# MMCSD8_MMC_CTLCFG_0FA00000h register map
Vendor: Texas Instruments
Peripheral module from a debugger description file (folder AM275x).
Registers are 16-bit, read-write, reset 0x0 unless marked. A register's access mark holds for its fields unless they carry their own. Offsets are as the file gives them; lines under a group give offsets from that group; [hi:lo] are bit positions; {n}, {i} and the like mark numbered series; 'fields as' and 'values as' point back to an identical list; <NAME> marks a mode.

## mmc_ctlcfg (part 1 of 4)
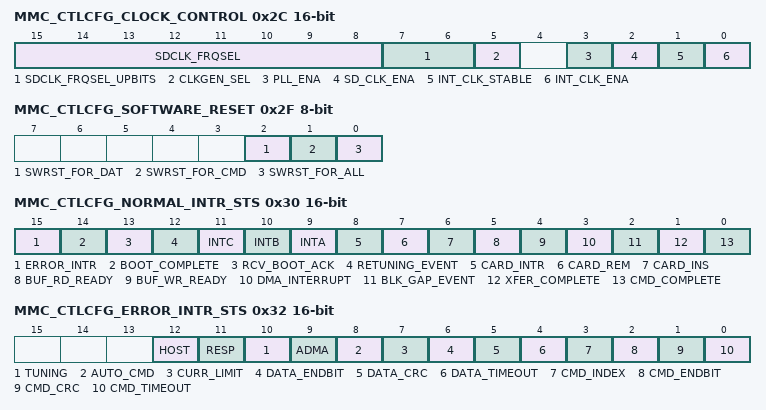
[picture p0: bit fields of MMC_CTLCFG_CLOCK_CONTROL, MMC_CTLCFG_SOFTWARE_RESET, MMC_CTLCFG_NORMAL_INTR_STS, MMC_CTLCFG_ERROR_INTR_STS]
0x2C MMC_CTLCFG_CLOCK_CONTROL access per field — This register is used to program the Clock frequency select, generator select, Clock enable, Internal Clock state fields This register controls SDCLK in SD Mode and RCLK in UHS-II mode.
  [15:8] SDCLK_FRQSEL rw — This register is used to select the frequency of the SDCLK pin. The frequency is not programmed directly; rather this register holds the divisor of the Base Clock Frequency For SD clock in the capabilities register. Only the following settings are allowed. [1] 8-bit Divided Clock Mode 80h - base clock divided by 256 40h - base clock divided by 128 20h - base clock divided by 64 10h - base clock divided by 32 08h - base clock divided by 16 04h - base clock divided by 8 02h - base clock divided by 4 01h - base clock divided by 2 00h - base clock[10MHz-63MHz]Setting 00h specifies the highest frequency of the SD Clock. When setting multiple bits, the most significant bit is used as the divisor. But multiple bits should not be set. The two default divider values can be calculated by the frequency that is defined by the Base Clock Frequency For SD Clock in the Capabilities register. [1] 25 MHz divider value. [2] 400 KHz divider value.The frequency of the SDCLK is set by the following formula:Clock Frequency = [Baseclock] / divisor.Thus choose the smallest possible divisor which results in a clock frequency that is less than or equal to the target frequency.Maximum Frequency for SD = 50Mhz [base clock]Maximum Frequency for MMC = 52Mhz [base clock]Minimum Frequency = 195.3125Khz [50Mhz / 256], same calculation for MMC also. [2] 10-bit Divided Clock ModeHost Controller Version 3.00 supports this mandatory mode instead of the 8-bit Divided Clock Mode. The length of divider is extended to10 bits and all divider values shall be supported. 3FFh --1/2046 Divided Clock N -------1/2N Divided Clock [Duty 50%] 002h -- 1/4 Divided Clock 001h ---1/2 Divided Clock 000h --- Base Clock [10MHz-254MHz] Reset Source: vbus_amod_g_rst_n
  [7:6] SDCLK_FRQSEL_UPBITS rw — Bit 07-06 is assigned to bit 09-08 of clock divider in SDCLK Frequency Select. Reset Source: vbus_amod_g_rst_n
  [5] CLKGEN_SEL rw — This bit is used to select the clock generator mode in SDCLK Frequency Select. If the Programmable Clock Mode is supported [non-zero value is set to Clock Multiplier in the Capabilities register], this bit attribute is RW, and if not supported, this bit attribute is RO and zero is read. This bit depends on the setting of Preset Value Enable in the Host Control 2 register. If the Preset Value Enable = 0, this bit is set by Host Driver. If the Preset Value Enable = 1, this bit is automatically set to a value specified in one of Preset Value registers. '0' Divided Clock Mode '1' Programmable Clock Mode 0 Divided Clock Mode1 Programmable Clock Mode
  [3] PLL_ENA rw — This bit is added from Version 4.10 for Host Controller using PLL. This feature allows Host Controller to initialize clock generator in two steps: by Internal Clock Enable and PLL Enable and to minimize output latency [ex. SDCLK/RCLK, D0lane] from SD Clock Enable. There are two modes to keep Host Drivers compatibility. In both modes, PLL Locked timing is indicated by Internal Clock Stable. [1] When Host Version 4 Enable =0 [Host Driver Version 3, which does not support this bit] or this bit is not implemented,Internal Clock Enable [or SD Clock Enable] may activate PLL [exit low power mode and start locking clock]. [2] When Host Version 4 Enable =1 [Host Driver Version 4],Internal Clock Enable is set before setting this bit and then setting this bit may activate PLL [exit low power mode and start locking clock]. 0 PLL is in low power mode1 PLL is enabled
  [2] SD_CLK_ENA rw — The HC shall stop SDCLK when Writing this bit to 0. SDCLK frequency Select can be changed when this bit is 0. Then, the HC shall maintain the same clock frequency until SDCLK is stopped [Stop at SDCLK = 0]. If the HC detects the No Card state, this bit shall be cleared. 0 Disable providing SDCLK1 Enable providing SDCLK
  [1] INT_CLK_STABLE ro — This bit is set to 1 when SD clock is stable after Writing to Internal Clock Enable in this register to 1. The SD Host Driver shall wait to set SD Clock Enable until this bit is set to 1. Note: This is useful when using PLL for a clock oscillator that requires setup time. 0 Not Ready1 Ready
  [0] INT_CLK_ENA rw — This bit is set to 0 when the HD is not using the HC or the HC awaits a wakeup event. The HC should stop its internal clock to go very low power state. Still, registers shall be able to be read and written. Clock starts to oscillate when this bit is set to 1. When clock oscillation is stable, the HC shall set Internal Clock Stable in this register to 1. This bit shall not affect card detection. 0 Stop1 Oscillate
0x2E MMC_CTLCFG_TIMEOUT_CONTROL 8-bit — The register sets the Data Timeout counter value
  [3:0] COUNTER_VALUE — This value determines the interval by which DAT line time-outs are detected. Refer to the Data Time-out Error in the Error Interrupt Status register for information on factors that dictate time-out generation. Time-out clock frequency will be generated by dividing the sdclockTMCLK by this value. When setting this register, prevent inadvertent time-out events by clearing the Data Time-out Error Status Enable [in the Error Interrupt Status Enable register]. 1111 - Reserved 1110 - TMCLK * 2^27 -------------------- -------------------- 0001 - TMCLK * 2^14 0000 - TMCLK * 2^13 Reset Source: vbus_amod_g_rst_n
0x2F MMC_CTLCFG_SOFTWARE_RESET 8-bit — This register is used to program the software reset for data, command and for all
  [2] SWRST_FOR_DAT — Only part of data circuit is reset. The following registers and bits are cleared by this bit: Buffer Data Port Register: Buffer is cleared and Initialized. Present State register: Buffer read Enable, Buffer write Enable, Read Transfer Active, Write Transfer Active, DAT Line Active, Command Inhibit [DAT]. Block Gap Control register: Continue Request, Stop At Block Gap Request. Normal Interrupt Status register: Buffer Read Ready, Buffer Write Ready, Block Gap Event, Transfer Complete. 0 Work1 Reset
  [1] SWRST_FOR_CMD — Software Reset For CMD Line Only part of command circuit is reset to be able to issue a command. From Version 4.10, this bit is also used to initialize UHS-II command circuit. This reset is effective only command issuing circuit [including response error statuses related to Com-mand Inhibit [CMD] control] and does not affect data transfer circuit. Host Controller can continue data transfer even this reset is executed during handling of sub com- mand response errors. The following registers and bits are cleared by this bit: Present State register Command Inhibit [CMD] Normal Interrupt Status register Command Complete Error Interrupt Status [from Version 4.10] Response error statuses related to Com-mand Inhibit [CMD] 0 Work1 Reset
  [0] SWRST_FOR_ALL — This reset affects the entire HC except for the card detection circuit. Register bits of type ROC, RW, RW1C, RWAC are cleared to 0. During its initialization, the HD shall set this bit to 1 to reset the HC. The HC shall reset this bit to 0 when capabilities registers are valid and the HD can read them. Additional use of Software Reset For All may not affect the value of the Capabilities registers. If this bit is set to 1, the SD card shall reset itself and must be re initialized by the HD. 0 Work1 Reset
0x30 MMC_CTLCFG_NORMAL_INTR_STS access not given — This register gives the status of all the interrupts
  [15] ERROR_INTR ro — If any of the bits in the Error Interrupt Status Register are set, then this bit is set. Therefore the HD can test for an error by checking this bit first. In UHS-II mode is enabled, if any of the bits in the UHS-II Error Interrupt Status register are set, this bit is also set. '0' No error '1' Error 0 No Interrupt1 Error interrupt is generated
  [14] BOOT_COMPLETE — This status is set if the boot operation gets terminated. '0' Boot operation is not terminated '1' Boot operation is terminated 0 No Interrupt1 Boot Terminate interrupt is generated (access R/W1TC)
  [13] RCV_BOOT_ACK — This status is set if the boot acknowledge is received from device. '0' Boot ack not recieved '1' Boot ack is recieved 0 No Interrupt1 Boot acknowledge is received (access R/W1TC)
  [12] RETUNING_EVENT ro — This status is set if Re-Tuning Request in the Present State register changes from 0 to 1. Host Controller requests Host Driver to perform re-tuning for next data transfer. Current data transfer [not large block count] can be completed without re-tuning.In UHS-II mode, this bit is not effective '0' Re-tuning not required '1' Re-tuning should be performed Reset Source: vbus_amod_g_rst_n
  [11] INTC ro — This status is set if INT_C is enabled and INT_C# pin is in low level. Writing this bit to 1 does not clear this bit. It is cleared by resetting the INT_C interrupt factor. Reset Source: vbus_amod_g_rst_n
  [10] INTB ro — This status is set if INT_B is enabled and INT_B# pin is in low level. Writing this bit to 1 does not clear this bit. It is cleared by resetting the INT_B interrupt factor. Reset Source: vbus_amod_g_rst_n
  [9] INTA ro — This status is set if INT_A is enabled and INT_A# pin is in low level. Writing this bit to 1 does not clear this bit. It is cleared by resetting the INT_A interrupt factor.NOTE : INT_A, INT_B, and INT_C are to be implemented based on the Application Requirements. By default these are not implemented as there is no specific requirement from Customers. Reset Source: vbus_amod_g_rst_n
  [8] CARD_INTR ro — When this status has been set and the Host Driver needs to start this interrupt service, Card Interrupt Status Enable in the Normal Interrupt Status Enable register may be set to 0 in order to clear the card interrupt status latched in the Host Controller and to stop driv-ing the interrupt signal to the Host System.After completion of the card interrupt service [It should reset interrupt factors in the SD card and the interrupt signal may not be asserted],set Card Interrupt Status Enable to 1 and start sampling the interrupt signal again. Writing this bit to 1 does not clear this bit. It is cleared by resetting the SD card interrupt fac-tor. [1] DAT[1] Interrupt Input in SD Mode In 1-bit mode, the Host Controller shall detect the Card Interrupt without SD Clock to support wakeup. In 4-bit mode, the card interrupt sig-nal is sampled during the interrupt cycle, so there are some sample delays between the interrupt signal from the SD card and the inter-rupt to the Host System. Interrupt detected by DAT[1] is supported when there is a card per slot. In case of UHS-I mode, switching time of Interrupt Period is relaxed for 2 clock cycles. Then Host Controller needs to delay start of interrupt sampling at least 2 clocks and should sample interrupt while Interrupt Period is sta-ble. [2] DAT[2] Interrupt Input in UHS-II Mode When Card Inserted in the Present State reg-ister and SD Bus Power for VDD1 in the Power Control register are set to 1, Host Con-troller configures DAT[2] as Interrupt Input and enables pull-up of DAT[2]. DAT[2] interrupt is asynchronous to RCLK, low level sensitive and 3.3V signal level. DAT[2] interrupt is masked by setting Card Interrupt Status Enable to 0 in the Normal Interrupt register.When either Card Inserted or SD Bus Power for VDD1 is set to 0, Host Controller sets DAT[2] to low. Only point to point connection is allowed between Host and Card. [3] INT MSG in UHS-II Mode INT MSG is enabled by setting INT MSG Enable in the UHS-II Device Select register. DAT[2] and INT MSG interrupt sources are ORed and indicated to Card Interrupt. If any bit in the UHS-II Device Interrupt Status regis- ter is set to 1, INT MSG interrupt is generated. INT MSG interrupt is cleared by Writing a cor-respondent bit to 1 in the UHS-II Device Inter-rupt Status register. Masking DAT[2] interrupt also disables INT MSG interupt due to Card Interrupt Status Enable is set to 0. SDIO Ver-sion 4.00 does not support INT MSG. '0' No Card Interrupt '1' Generate Card Interrupt 0 No Interrupt1 Card interrupt is generated
  [7] CARD_REM — This status is set if the Card Inserted in the Present State register changes from 1 to 0. When the HD writes this bit to 1 to clear this status the status of the Card Inserted in the Present State register should be confirmed. Because the card detect may possibly be changed when the HD clear this bit an Interrupt event may not be generated. '0' Card State Stable or Debouncing '1' Card Removed 0 No Interrupt1 Card removal interrupt is generated (access R/W1TC)
  [6] CARD_INS — This status is set if the Card Inserted in the Present State register changes from 0 to 1.When the HD writes this bit to 1 to clear this status the status of the Card Inserted in the Present State register should be confirmed. Because the card detect may possibly be changed when the HD clear this bit an Interrupt event may not be generated. '0' Card State Stable or Debouncing '1' Card Inserted 0 No Interrupt1 Card insertion interrupt is generated (access R/W1TC)
  [5] BUF_RD_READY — This status is set if the Buffer Read Enable changes from 0 to 1. Buffer Read Ready is set to 1 for every CMD19 execution in tuning procedure.In UHS-II mode, this bit is set at FC [Flow Control] unit basis. '0' Not ready to read buffer, '1' Ready to read buffer 0 No Interrupt1 Buffer Read Ready interrupt is generated (access R/W1TC)
  [4] BUF_WR_READY — This status is set if the Buffer Write Enable changes from 0 to 1.In UHS-II mode, this bit is set at FC [Flow Control] unit basis. '0' Not ready to write to buffer, '1' Ready to write to buffer 0 No Interrupt1 Buffer Write Ready interrupt is generated (access R/W1TC)
  [3] DMA_INTERRUPT — This status is set if the HC detects the Host DMA Buffer Boundary in the Block Size regiser. '0' No DMA Interrupt '1' DMA Interrupt is generated 0 No Interrupt1 DMA interrupt is generated (access R/W1TC)
  [2] BLK_GAP_EVENT — If the Stop At Block Gap Request in the BlockGap Control Register is set, this bit is set. Read Transaction:This bit is set at the falling edge of the DAT Line Active Status [When the transaction is stopped at SD Bus timing. The Read Wait must be supported inorder to use this function]. Write Transaction:This bit is set at the falling edge of Write Transfer Active Status [After getting CRC status at SD Bus timing]. In UHS-II mode, this bit is set at FC [Flow Control] unit basis. '0' No Block Gap Event '1' Transaction stopped at Block Gap 0 No Interrupt1 Block Gap Event is generated (access R/W1TC)
  [1] XFER_COMPLETE — This bit is set when a read / write transaction is completed. SD Mode Read Transaction:This bit is set at the falling edge of Read Transfer Active Status. There are two cases in which the Interrupt is generated. The first is when a data transfer is completed as specified by data length [After the last data has been read to the Host Sys- tem]. The second is when data has stopped at the block gap and completed the data transfer by setting the Stop At Block Gap Request in the Block Gap Control Register [After valid data has been read to the Host System]. Write Transaction:This bit is set at the falling edge of the DAT Line Active Status. There are two cases in which the Interrupt is generated. The first is when the last data is written to the card as specified by data length and Busy signal is released. The second is when data transfers are stopped at the block gap by setting Stop At Block Gap Request in the Block Gap Control Register and data transfers completed. [After valid data is written to the SD card and the busy signal is released].Note: Transfer Complete has higher priority than Data Time-out Error. If both bits are set to 1, the data transfer can be considered complete.Note: While performing tuning procedure [Execute Tuning is set to 1], Transfer Complete is not set to 1 Command with Busy:This bit is set when busy is de-asserted. Refer to DAT Line Active and Command Inhibit[DAT] in the Present State register.UHS-I mode While performing tuning procedure [Execute Tuning is set to 1], Transfer Complete is not set to 1. '0' No Data Transfer Complete, '1' Data Transfer Complete UHS-II Mode This interrupt is generated in following twocases: [a] EBSY Completion [for EBSY supported commands] When EBSY Wait in the UHS-II Transfer Mode register is set to 1, this bit is set when EBSY packet has been received, and all valid data have been sent to system memory in case of read operation. [b] Stop and Continue during DCMD Data Transfer When Stop At Block Gap Request in the Block Gap Control register is set to 1 and data transfer is stopped at the Flow Control. Following is for both SD mode and UHS-II mode.The table below shows that Transfer Com-plete has higher priority than Data Timeout Error. If both bits are set to 1, execution of a command can be considered to be completed. 1 - Command execution is completed 0 - Not complete 0 No Interrupt1 Transfer complete interrupt is generated (access R/W1TC)
  [0] CMD_COMPLETE — SD Mode This bit is set when we get the end bit of the command response [Except Auto CMD12 and Auto CMD23]Note: Command Time-out Error has higher priority than Command Complete. If both are set to 1, it can be considered that the response was not received correctly.Version 4.00 defines response check function for R1 and R5. If Response Interrupt Disable in the Transfer Mode register is set to 1, gen-eration of this interrupt is prohibited regardless of Command Complete Signal Enable. UHS-II ModeIf Response Interrupt Disable is set to 0 in the UHS-II Transfer Mode register, this interrupt is generated when response packet is received.If Response Interrupt Disable is set to 1 in the UHS-II Transfer Mode register, generation of this interrupt is prohibited regardless of Com-mand Complete Signal Enable. '0' No Command Complete, '1' Command Complete 0 No Interrupt1 Command complete interrupt is generated (access R/W1TC)
0x32 MMC_CTLCFG_ERROR_INTR_STS access not given — This register gives the status of the error interrupts
  [12] HOST — Occurs when detecting ERROR in m_hresp[dma transaction] 0 No Error1 Host Error (access R/W1TC)
  [11] RESP — Host Controller Version 4.00 supports response error check function to avoid overhead of response error check by Host Driver during DMA execution. If Response Error Check Enable is set to 1 in the Transfer Mode register, Host Controller Checks R1 or R5 response. If an error is detected in a response, this bit is set to 1.If Response Error Check Enable is set to 1 in the Transfer Mode register, Host Controller Checks R1 or R5 response. 0 No Error1 Response Error (access R/W1TC)
  [10] TUNING — This bit is set when an unrecoverable error is detected in a tuning circuit except during tuning procedure [Occurrence of an error during tuning procedure is indicated by Sampling Select]. By detectingTuning Error, Host Driver needs to abort a command executing and perform tuning.To reset tuning circuit, Sampling Clock shall be set to 0 before executing tuning procedure.The Tuning Error is higher priority than the other error interrupts generated during data transfer. By detecting Turning Error, the Host Driver should discard data transferred by a current read/write command and retry data transfer after the Host Controller retrieved from tuning circuit error. 0 No Error1 Tuning Error (access R/W1TC)
  [9] ADMA — This bit is set when the Host Controller detects errors during ADMA based data transfer. The state of the ADMA at an error occurrence is saved in the ADMA Error Status Register. 0 No Error1 ADMA Error (access R/W1TC)
  [8] AUTO_CMD — Auto CMD12 and Auto CMD23 use this error status.This bit is set when detecting that any of the bits D00 to D05 in Auto CMD Error Status register has changed from 0 to 1. D07 is effective in case of Auto CMD12. Auto CMD Error Status register is valid while this bit is set to 1 and may be cleared with clearing of this bit [another implementation is also allowed]. 0 No Error1 Auto CMD Error (access R/W1TC)
  [7] CURR_LIMIT — By setting the SD Bus Power bit in the Power Control Register, the HC is requested to supply power for the SD Bus. If the HC supports the Current Limit Function, it can be protected from an Illegal card by stopping power supply to the card in which case this bit indicates a failure status. Reading 1 means the HC is not supplying power to SD card due to some failure. Reading 0 means that the HC is supplying power and no error has occurred. This bit shall always set to be 0, if the HC does not support this function. 0 No Error1 Power Fail (access R/W1TC)
  [6] DATA_ENDBIT — Occurs when detecting 0 at the end bit position of read data which uses the DAT line or the end bit position of the CRC status. 0 No Error1 Data Endbit Error (access R/W1TC)
  [5] DATA_CRC — Occurs when detecting CRC error when transferring read data which uses the DAT line or when detecting the Write CRC Status having a value of other than 010. 0 No Error1 Data CRC Error (access R/W1TC)
  [4] DATA_TIMEOUT — Occurs when detecting one of following timeout conditions: 1. Busy Timeout for R1b, R5b type. 2. Busy Timeout after Write CRC status 3. Write CRC status Timeout 4. Read Data Timeout. 0 No Error1 Data Timeout Error (access R/W1TC)
  [3] CMD_INDEX — Occurs if a Command Index error occurs in the Command Response. 0 No Error1 Command Index Error (access R/W1TC)
  [2] CMD_ENDBIT — Occurs when detecting that the end bit of a command response is 0. 0 No Error1 Command End bit Error (access R/W1TC)
  [1] CMD_CRC — Command CRC Error is generated in two cases. 1. If a response is returned and the Command Time-out Error is set to 0, this bit is set to 1 when detecting a CRT error in the command response 2. The HC detects a CMD line conflict by monitoring the CMD line when a command is issued. If the HC drives the CMD line to 1 level, but detects 0 level on the CMD line at the next SDCLK edge, then the HC shall abort the command [Stop driving CMD line] and set this bit to 1. The Command Timeout Error shall also be set to 1 to distinguish CMD line conflict. 0 No Error1 Command CRC Error (access R/W1TC)
  [0] CMD_TIMEOUT — Occurs only if the no response is returned within 64 SDCLK cycles from the end bit of the command. If the HC detects a CMD line conflict, in which case Command CRC Error shall also be set. This bit shall be set without waiting for 64 SDCLK cycles because the command will be aborted by the HC. 0 No Error1 Command Timeout Error (access R/W1TC)
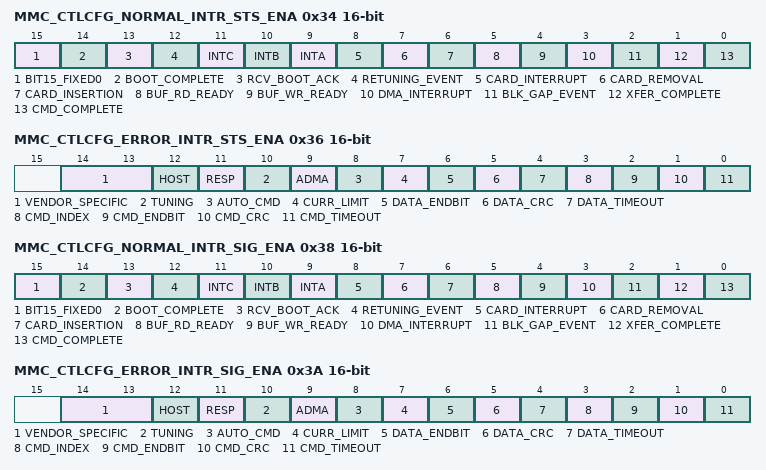
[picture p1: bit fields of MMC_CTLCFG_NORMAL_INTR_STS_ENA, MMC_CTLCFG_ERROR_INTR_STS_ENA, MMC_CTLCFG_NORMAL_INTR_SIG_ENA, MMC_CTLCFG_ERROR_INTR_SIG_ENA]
0x34 MMC_CTLCFG_NORMAL_INTR_STS_ENA access per field — This register is used to enable the normal interrupt status register fields
  [15] BIT15_FIXED0 ro — The HC shall control error Interrupts using the Error Interrupt Status Enable register. Reset Source: vbus_amod_g_rst_n
  [14] BOOT_COMPLETE rw — '0' Masked '1' Enabled 0 Masked1 Enabled
  [13] RCV_BOOT_ACK rw — '0' Masked '1' Enabled 0 Masked1 Enabled
  [12] RETUNING_EVENT rw — 0 - Masked 1 - Enabled 0 Masked1 Enabled
  [11] INTC rw — If this bit is set to 0, the Host Controller shall clear the interrupt request to the System. The Host Driver may clear this bit before servicing the INT_C and may set this bit again after all interrupt requests to INT_C pin are cleared to prevent inadvertent interrupts. 0 Masked1 Enabled
  [10] INTB rw — If this bit is set to 0, the Host Controller shall clear the interrupt request to the System. The Host Driver may clear this bit before servicing the INT_B and may set this bit again after all interrupt requests to INT_B pin are cleared to prevent inadvertent interrupts. 0 Masked1 Enabled
  [9] INTA rw — If this bit is set to 0, the Host Controller shall clear the interrupt request to the System. The Host Driver may clear this bit before servicing the INT_A and may set this bit again after all interrupt requests to INT_A pin are cleared to prevent inadvertent interrupts. 0 Masked1 Enabled
  [8] CARD_INTERRUPT rw — If this bit is set to 0, the HC shall clear Interrupt request to the System. The Card Interrupt detection is stopped when this bit is cleared and restarted when this bit is set to 1. The HD may clear the Card Interrupt Status Enable before servicing the Card Interrupt and may set this bit again after all Interrupt requests from the card are cleared to prevent inadvertent Interrupts. By setting this bit to 0, interrupt input should be masked by implementation so that the interrupt Input is not affected by external signal in any state [ex. floating]. 0 Masked1 Enabled
  [7] CARD_REMOVAL rw — '0' Masked '1' Enabled 0 Masked1 Enabled
  [6] CARD_INSERTION rw — '0' Masked '1' Enabled 0 Masked1 Enabled
  [5] BUF_RD_READY rw — '0' Masked '1' Enabled 0 Masked1 Enabled
  [4] BUF_WR_READY rw — '0' Masked '1' Enabled 0 Masked1 Enabled
  [3] DMA_INTERRUPT rw — '0' Masked, '1' Enabled 0 Masked1 Enabled
  [2] BLK_GAP_EVENT rw — '0' Masked '1' Enabled 0 Masked1 Enabled
  [1] XFER_COMPLETE rw — '0' Masked '1' Enabled 0 Masked1 Enabled
  [0] CMD_COMPLETE rw — '0' Masked '1' Enabled 0 Masked1 Enabled
0x36 MMC_CTLCFG_ERROR_INTR_STS_ENA — This register is used to enable the Error Interrupt Status register fields
  [14:13] VENDOR_SPECIFIC — N/A Reset Source: vbus_amod_g_rst_n
  [12] HOST — '0' Masked '1' Enabled 0 Masked1 Enabled
  [11] RESP — '0' Masked '1' Enabled 0 Masked1 Enabled
  [10] TUNING — '0' Masked '1' Enabled 0 Masked1 Enabled
  [9] ADMA — '0' Masked '1' Enabled 0 Masked1 Enabled
  [8] AUTO_CMD — '0' Masked '1' Enabled 0 Masked1 Enabled
  [7] CURR_LIMIT — '0' Masked '1' Enabled 0 Masked1 Enabled
  [6] DATA_ENDBIT — '0' Masked '1' Enabled 0 Masked1 Enabled
  [5] DATA_CRC — '0' Masked '1' Enabled 0 Masked1 Enabled
  [4] DATA_TIMEOUT — '0' Masked '1' Enabled 0 Masked1 Enabled
  [3] CMD_INDEX — '0' Masked '1' Enabled 0 Masked1 Enabled
  [2] CMD_ENDBIT — '0' Masked '1' Enabled 0 Masked1 Enabled
  [1] CMD_CRC — '0' Masked '1' Enabled 0 Masked1 Enabled
  [0] CMD_TIMEOUT — '0' Masked '1' Enabled 0 Masked1 Enabled
0x38 MMC_CTLCFG_NORMAL_INTR_SIG_ENA access per field — This register is used to enable the Normal Interrupt Signal register
  [15] BIT15_FIXED0 ro — The HD shall control error Interrupts using the Error Interrupt Signal Enable register. Reset Source: vbus_amod_g_rst_n
  [14] BOOT_COMPLETE rw — '0' Masked '1' Enabled 0 Masked1 Enabled
  [13] RCV_BOOT_ACK rw — '0' Masked '1' Enabled 0 Masked1 Enabled
  [12] RETUNING_EVENT rw — '0' Masked '1' Enabled 0 Masked1 Enabled
  [11] INTC rw — '0' Masked '1' Enabled 0 Masked1 Enabled
  [10] INTB rw — '0' Masked '1' Enabled 0 Masked1 Enabled
  [9] INTA rw — '0' Masked '1' Enabled 0 Masked1 Enabled
  [8] CARD_INTERRUPT rw — '0' Masked '1' Enabled 0 Masked1 Enabled
  [7] CARD_REMOVAL rw — '0' Masked '1' Enabled 0 Masked1 Enabled
  [6] CARD_INSERTION rw — '0' Masked '1' Enabled 0 Masked1 Enabled
  [5] BUF_RD_READY rw — '0' Masked '1' Enabled 0 Masked1 Enabled
  [4] BUF_WR_READY rw — '0' Masked '1' Enabled 0 Masked1 Enabled
  [3] DMA_INTERRUPT rw — '0' Masked '1' Enabled 0 Masked1 Enabled
  [2] BLK_GAP_EVENT rw — '0' Masked '1' Enabled 0 Masked1 Enabled
  [1] XFER_COMPLETE rw — '0' Masked '1' Enabled 0 Masked1 Enabled
  [0] CMD_COMPLETE rw — '0' Masked '1' Enabled 0 Masked1 Enabled
0x3A MMC_CTLCFG_ERROR_INTR_SIG_ENA — This register is used to enable Error Interrupt Signal register
  fields as MMC_CTLCFG_ERROR_INTR_STS_ENA
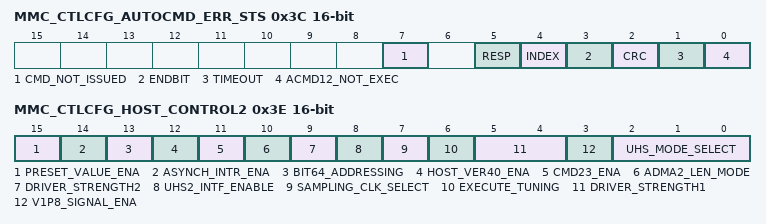
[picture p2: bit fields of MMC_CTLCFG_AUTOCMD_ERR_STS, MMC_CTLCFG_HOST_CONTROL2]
0x3C MMC_CTLCFG_AUTOCMD_ERR_STS ro — This register is used to indicate CMD12 response error of Auto CMD12 and CMD23 response error of Auto CMD 23
  [7] CMD_NOT_ISSUED — Setting this bit to 1 means CMD_wo_DAT is not executed due to an Auto CMD12 error [D04- D01] in this register. This bit is set to 0 when Auto CMD Error is generated by Auto CMD23. 0 No Error1 Not Issued
  [5] RESP — This bit is set when Response Error Check Enable in the Transfer Mode register is set to 1 and an error is detected in R1 response of either Auto CMD12 or Auto CMD23. This status should be ignored if any bit of D00 to D04 is set to 1. 0 No Error1 Auto Command Response Error
  [4] INDEX — Occurs if the Command Index error occurs in response to a command. 0 No Error1 Auto Command Index Error
  [3] ENDBIT — Occurs when detecting that the end bit of command response is 0. 0 No Error1 Auto Command End Bit Error
  [2] CRC — Occurs when detecting a CRC error in the command response. 0 No Error1 Auto Command CRC Error
  [1] TIMEOUT — Occurs if the no response is returned within 64 SDCLK cycles from the end bit of the command.If this bit is set to 1, the other error status bits [D04 - D02] are meaningless. 0 No Error1 Auto Command Timeout Error
  [0] ACMD12_NOT_EXEC — If memory multiple block data transfer is not started due to command error, this bit is not set because it is not necessary to issue Auto CMD12. Setting this bit to 1 means the HC cannot issue Auto CMD12 to stop memory multiple block transfer due to some error. If this bit is set to 1, other error status bits [D04 - D01] are meaningless. This bit is set to 0 when Auto CMD Error is generated by Auto CMD23 0 No Error1 Not Executed
0x3E MMC_CTLCFG_HOST_CONTROL2 — This register is used to program UHS Select Mode,UHS Select Mode,Driver Strength Select,Execute Tuning,Sampling Clock Select,Asynchronous Interrupt Enable and Preset value enable
  [15] PRESET_VALUE_ENA — Host Controller Version 3.00 supports this bit. As the operating SDCLK frequency and I/O driver strength depend on the Host System implementation, it is difficult to determine these parameters in the Standard Host Driver. When Preset Value Enable is set to automatic. This bit enables the functions defined in the Preset Value registers.If this bit is set to 0, SDCLK Frequency Select, Clock Generator Select in the Clock Control register and Driver Strength Select in Host Control 2 register are set by Host Driver.If this bit is set to 1, SDCLK Frequency Select, Clock Generator Select in the Clock Control register and Driver Strength Select in Host Control 2 register are set by Host Controller as specified in the Preset Value registers. 0 SDCLK and Driver Strength are controlled by Host Driver1 Automatic Selection by Preset Value are Enabled
  [14] ASYNCH_INTR_ENA — This bit can be set to 1 if a card support asynchronous interrupt and Asynchronous Interrupt Support is set to 1 in the Capabilities register. Asynchronous interrupt is effective when DAT[1] interrupt is used in 4-bit SD mode [and zero is set to Interrupt Pin Select in the Shared Bus Control register]. If this bit is set to 1, the Host Driver can stop the SDCLK during asynchronous interrupt period to save power. During this period, the Host Controller continues to deliver Card Interrupt to the host when it is asserted by the Card. 0 Asynchronous Interrupt disabled1 Asynchronous Interrupt enabled
  [13] BIT64_ADDRESSING — This field is effective when Host Version 4.00 Enable is set to 1. Host Controller selects either of 32-bit or 64-bit addressing modes to access system memory. Whether 32-bit or 64-bit is determined by OS installed in a host system. Host Driver setsthis bit depends on addressing mode of installed OS. Refer to 64-bit System Address Support in the Capabilities register.. 0 32 bit addressing1 64 bit addressing
  [12] HOST_VER40_ENA — This bit selects either Version 3.00 compatible mode or Ver4.mode. In Version 4.00, support of 64-bit System Addressing is modified. All DMAs support 64-bit System Addressing. UHS-IIsupported Host Driver shall enable this bit. In Version 4.10, supported 32-bit Block Count for all operations. Functions of following fields are modified. SDMA Address SDMA uses ADMA System Address register [05Fh-058h] instead of SDMA System Address register [Offset 003-000h] ADMA2 / ADMA3 Selection ADMA3 is selected by DMA Select in the Host Control 1 regis-ter. 64bit ADMA Descriptor Size 128bit descriptor is used instead of 96-bit descriptor when 64-bit Addressing is set to 1. Selection of 32-bit / 64-bit System Addressing Either 32-bit or 64-bit system addressing is selected by 64-bit Addressing bit in this register instead of DMA Select in the Host Control 1 register. 32-bit Block Count SDMA System Address register [003h-000h] is modified to 32-bit Block Count register. 0 Version 3.00 Compatible Mode1 Version 4 Mode
  [11] CMD23_ENA — In memory card initialization, Host Driver Version 4.10 checks whether card supports CMD23 by checking a bit SCR[33]. If the card supports CMD23 [SCR[33]=1], this bit is set to 1. This bit is used to select Auto CMD23 or Auto CMD12 for ADMA3 datatransfer. Refer to Auto CMD Enable in the Transfer Mode regis-ter. 0 CMD23 Disable1 CMD23 Enable
  [10] ADMA2_LEN_MODE — This bit selects one of ADMA2 Length Modes either 16-bit or 26-bit. 0 16-bit Data Length Mode1 26-bit Data Length Mode
  [9] DRIVER_STRENGTH2 — This is the programmed Drive STrength output and Bit[2] of the sdhccore_drivestrength value. Reset Source: vbus_amod_g_rst_n
  [8] UHS2_INTF_ENABLE — This bit is used to enable UHS-II Interface. Before trying to start UHS-II initialization, this bit shall be set to 1. Before trying to start SD mode initialization, this bit shall be set to 0. This bit is used to enable UHS-II IF Detection, Lane Synchroni-zation and In Dormant State in the Present State register, and to select clock source of either SD mode or UHS-II mode. Host Controller shall not leave unused SD 4-bit Interface lines [CLK, CMD and DAT[3:2]] floating in UHS-II mode by using pull-up or driving to low. When DAT[2] is used as interrupt input in UHS-II mode, DAT[2] of Host Controller is set to input and then DAT[2] of SDIO card is set to output to avoid conflict. '0' 4-bit SD Interface enabled '1' UHS-II Interface enabled 0 4-bit SD Interface enabled1 UHS-II Interface enabled
  [7] SAMPLING_CLK_SELECT — This bit is set by tuning procedure when Execute Tuning is cleared. Writing 1 to this bit is meaningless and ignored. Setting 1 means that tuning is completed successfully and setting 0 means that tuning is failed. Host Controller uses this bit to select sampling clock to receive CMD and DAT. This bit is cleared by Writing 0. Change of this bit is not allowed while the Host Controller is receiving response or a read data block. 0 Fixed clock is used to sample data1 Tuned clock is used to sample data
  [6] EXECUTE_TUNING — This bit is set to 1 to start tuning procedure and automatically cleared when tuning procedure is completed. The result of tuning is indicated to Sampling Clock Select. Tuning procedure is aborted by Writing 0 for more detail about tuning procedure. '0' Not Tuned or Tuning Completed '1' Execute Tuning Reset Source: vbus_amod_g_rst_n
  [5:4] DRIVER_STRENGTH1 — Host Controller output driver in 1.8V signaling is selected by this bit. In 3.3V signaling, this field is not effective. This field can be set depends on Driver Type A, C and D support bits in the Capabilities register. This bit depends on setting of Preset Value Enable.If Preset Value Enable = 0, this field is set by Host Driver. If Preset Value Enable = 1, this field is automatically set by a value specified in the one of Preset Value registers. 0 Driver Type B is Selected (Default)1 Driver Type A is Selected2 Driver Type C is Selected3 Driver Type D is Selected
  [3] V1P8_SIGNAL_ENA — This bit controls voltage regulator for I/O cell. 3.3V is supplied to the card regardless of signaling voltage. Setting this bit from 0 to 1 starts changing signal voltage from 3.3V to 1.8V.1.8V regulator output shall be stable within 5ms. Host Controller clears this bit if switching to 1.8V signaling fails. Clearing this bit from 1 to 0 starts changing signal voltage from 1.8V to 3.3V.3.3V regulator output shall be stable within 5ms. Host Driver can set this bit to 1 when Host Controller supports 1.8V signaling [One of support bits is set to 1: SDR50, SDR104 or DDR50 in the Capabilities register] and the card or device supports UHS-I. '0' 3.3V Signalling, '1' 1.8V Signalling 0 3.3V Signalling1 1.8V Signalling
  [2:0] UHS_MODE_SELECT — This field is used to select one of UHS-I modes or UHS-II mode.In case of UHS-I mode, this field is effective when 1.8V Signal-ing Enable is set to 1. In case of UHS-II mode, 1.8V SignalingEnable shall be set to 0. Setting of this field is used to select one of preset values in UHS-I or UHS-II mode. If Preset Value Enable in the Host Control 2 register is set to 1,Host Controller sets SDCLK/RCLK Frequency Select, Clock Generator Select in the Clock Control register and DriverStrength Select according to Preset Value registers. In this case, one of preset value registers is selected by this field. Host Driver needs to reset SD Clock Enable before changing this field to avoid generating clock glitch. After setting this field, Host Driver sets SD Clock Enable again.When SDR50, SDR104 or DDR50 is selected for SDIO card, interrupt detection at the block gap shall not be used. Read Wait timing is changed for these modes. Refer to the SDIO Specification Version 3.00 for more detail. 0 SDR121 SDR252 SDR503 SDR1044 DDR505 HS4006 Reserved7 UHS-II
